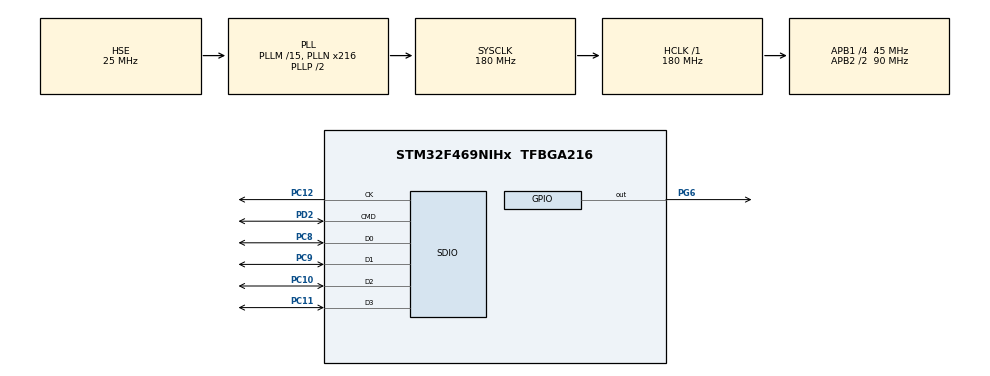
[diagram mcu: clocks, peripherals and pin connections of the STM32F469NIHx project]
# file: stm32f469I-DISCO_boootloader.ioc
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Dma.Request0=SDIO_RX
Dma.Request1=SDIO_TX
Dma.SDIO_RX.0.Direction=DMA_PERIPH_TO_MEMORY
Dma.SDIO_RX.0.FIFOMode=DMA_FIFOMODE_ENABLE
Dma.SDIO_RX.0.FIFOThreshold=DMA_FIFO_THRESHOLD_FULL
Dma.SDIO_RX.0.Instance=DMA2_Stream3
Dma.SDIO_RX.0.MemBurst=DMA_MBURST_INC4
Dma.SDIO_RX.0.MemDataAlignment=DMA_MDATAALIGN_WORD
Dma.SDIO_RX.0.MemInc=DMA_MINC_ENABLE
Dma.SDIO_RX.0.Mode=DMA_PFCTRL
Dma.SDIO_RX.0.PeriphBurst=DMA_PBURST_INC4
Dma.SDIO_RX.0.PeriphDataAlignment=DMA_PDATAALIGN_WORD
Dma.SDIO_RX.0.PeriphInc=DMA_PINC_DISABLE
Dma.SDIO_RX.0.Priority=DMA_PRIORITY_LOW
Dma.SDIO_TX.1.Direction=DMA_MEMORY_TO_PERIPH
Dma.SDIO_TX.1.FIFOMode=DMA_FIFOMODE_ENABLE
Dma.SDIO_TX.1.FIFOThreshold=DMA_FIFO_THRESHOLD_FULL
Dma.SDIO_TX.1.Instance=DMA2_Stream6
Dma.SDIO_TX.1.MemBurst=DMA_MBURST_INC4
Dma.SDIO_TX.1.MemDataAlignment=DMA_MDATAALIGN_WORD
Dma.SDIO_TX.1.MemInc=DMA_MINC_ENABLE
Dma.SDIO_TX.1.Mode=DMA_PFCTRL
Dma.SDIO_TX.1.PeriphBurst=DMA_PBURST_INC4
Dma.SDIO_TX.1.PeriphDataAlignment=DMA_PDATAALIGN_WORD
Dma.SDIO_TX.1.PeriphInc=DMA_PINC_DISABLE
Dma.SDIO_TX.1.Priority=DMA_PRIORITY_LOW
FATFS.USE_DMA_CODE_SD=1
FATFS._MAX_SS=4096
FREERTOS.Tasks01=defaultTask,0,128,StartDefaultTask,Default,NULL
Mcu.Family=STM32F4
Mcu.Name=STM32F469NIHx
Mcu.Package=TFBGA216
NVIC.DMA2_Stream3_IRQn=true\:5\:0\:false\:false\:true\:true\:false\:true
NVIC.DMA2_Stream6_IRQn=true\:5\:0\:false\:false\:true\:true\:false\:true
NVIC.PriorityGroup=NVIC_PRIORITYGROUP_4
NVIC.SDIO_IRQn=true\:5\:0\:false\:false\:true\:true\:true\:true
NVIC.TIM6_DAC_IRQn=true\:0\:0\:false\:false\:true\:false\:false\:true
NVIC.TimeBase=TIM6_DAC_IRQn
NVIC.TimeBaseIP=TIM6
PC10.Mode=SD_4_bits_Wide_bus
PC10.Signal=SDIO_D2
PC11.Mode=SD_4_bits_Wide_bus
PC11.Signal=SDIO_D3
PC12.Mode=SD_4_bits_Wide_bus
PC12.Signal=SDIO_CK
PC8.Mode=SD_4_bits_Wide_bus
PC8.Signal=SDIO_D0
PC9.Mode=SD_4_bits_Wide_bus
PC9.Signal=SDIO_D1
PD2.Mode=SD_4_bits_Wide_bus
PD2.Signal=SDIO_CMD
PG6.Signal=GPIO_Output
PH0/OSC_IN.Mode=HSE-External-Oscillator
PH0/OSC_IN.Signal=RCC_OSC_IN
PH1/OSC_OUT.Mode=HSE-External-Oscillator
PH1/OSC_OUT.Signal=RCC_OSC_OUT
ProjectManager.HeapSize=0x200
ProjectManager.StackSize=0x400
ProjectManager.TargetToolchain=TrueSTUDIO
RCC.AHBFreq_Value=180000000
RCC.APB1CLKDivider=RCC_HCLK_DIV4
RCC.APB1Freq_Value=45000000
RCC.APB1TimFreq_Value=90000000
RCC.APB2CLKDivider=RCC_HCLK_DIV2
RCC.APB2Freq_Value=90000000
RCC.APB2TimFreq_Value=180000000
RCC.CortexFreq_Value=180000000
RCC.HCLKFreq_Value=180000000
RCC.PLLM=15
RCC.PLLN=216
RCC.PLLQ=8
RCC.PLLSourceVirtual=RCC_PLLSOURCE_HSE
RCC.SYSCLKFreq_VALUE=180000000
RCC.SYSCLKSource=RCC_SYSCLKSOURCE_PLLCLK
RCC.USBFreq_Value=45000000
RCC.VCOOutputFreq_Value=360000000
VP_FATFS_VS_SDIO.Mode=SDIO
VP_FREERTOS_VS_CMSIS_V1.Mode=CMSIS_V1
VP_SYS_VS_tim6.Mode=TIM6
board=STM32F469I-DISCO

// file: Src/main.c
/* USER CODE BEGIN Header */
/**
  ******************************************************************************
  * @file           : main.c
  * @brief          : Main program body
  ******************************************************************************
  * @attention
  *
  * <h2><center>&copy; Copyright (c) 2019 STMicroelectronics.
  * All rights reserved.</center></h2>
  *
  * This software component is licensed by ST under Ultimate Liberty license
  * SLA0044, the "License"; You may not use this file except in compliance with
  * the License. You may obtain a copy of the License at:
  *                             www.st.com/SLA0044
  *
  ******************************************************************************
  */
/* USER CODE END Header */

#include "main.h"
#include "cmsis_os.h"
#include "fatfs.h"

SD_HandleTypeDef hsd;
DMA_HandleTypeDef hdma_sdio_rx;
DMA_HandleTypeDef hdma_sdio_tx;

osThreadId defaultTaskHandle;

void SystemClock_Config(void);
static void MX_GPIO_Init(void);
static void MX_DMA_Init(void);
static void MX_SDIO_SD_Init(void);
void StartDefaultTask(void const * argument);

int main(void)
{

  /* MCU Configuration--------------------------------------------------------*/

  /* Reset of all peripherals, Initializes the Flash interface and the Systick. */
  HAL_Init();

  /* Configure the system clock */
  SystemClock_Config();

  /* Initialize all configured peripherals */
  MX_GPIO_Init();
  MX_DMA_Init();
  MX_SDIO_SD_Init();

  /* Create the thread(s) */
  /* definition and creation of defaultTask */
  osThreadDef(defaultTask, StartDefaultTask, osPriorityNormal, 0, 128);
  defaultTaskHandle = osThreadCreate(osThread(defaultTask), NULL);

  /* Start scheduler */
  osKernelStart();

  /* We should never get here as control is now taken by the scheduler */

  /* Infinite loop */
  while (1)
  {

  }
}

void SystemClock_Config(void)
{
  RCC_OscInitTypeDef RCC_OscInitStruct = {0};
  RCC_ClkInitTypeDef RCC_ClkInitStruct = {0};
  RCC_PeriphCLKInitTypeDef PeriphClkInitStruct = {0};

  /** Configure the main internal regulator output voltage
  */
  __HAL_RCC_PWR_CLK_ENABLE();
  __HAL_PWR_VOLTAGESCALING_CONFIG(PWR_REGULATOR_VOLTAGE_SCALE1);
  /** Initializes the CPU, AHB and APB busses clocks
  */
  RCC_OscInitStruct.OscillatorType = RCC_OSCILLATORTYPE_HSE;
  RCC_OscInitStruct.HSEState = RCC_HSE_ON;
  RCC_OscInitStruct.PLL.PLLState = RCC_PLL_ON;
  RCC_OscInitStruct.PLL.PLLSource = RCC_PLLSOURCE_HSE;
  RCC_OscInitStruct.PLL.PLLM = 15;
  RCC_OscInitStruct.PLL.PLLN = 216;
  RCC_OscInitStruct.PLL.PLLP = RCC_PLLP_DIV2;
  RCC_OscInitStruct.PLL.PLLQ = 8;
  RCC_OscInitStruct.PLL.PLLR = 2;
  if (HAL_RCC_OscConfig(&RCC_OscInitStruct) != HAL_OK)
  {
    Error_Handler();
  }
  /** Activate the Over-Drive mode
  */
  if (HAL_PWREx_EnableOverDrive() != HAL_OK)
  {
    Error_Handler();
  }
  /** Initializes the CPU, AHB and APB busses clocks
  */
  RCC_ClkInitStruct.ClockType = RCC_CLOCKTYPE_HCLK|RCC_CLOCKTYPE_SYSCLK
                              |RCC_CLOCKTYPE_PCLK1|RCC_CLOCKTYPE_PCLK2;
  RCC_ClkInitStruct.SYSCLKSource = RCC_SYSCLKSOURCE_PLLCLK;
  RCC_ClkInitStruct.AHBCLKDivider = RCC_SYSCLK_DIV1;
  RCC_ClkInitStruct.APB1CLKDivider = RCC_HCLK_DIV4;
  RCC_ClkInitStruct.APB2CLKDivider = RCC_HCLK_DIV2;

  if (HAL_RCC_ClockConfig(&RCC_ClkInitStruct, FLASH_LATENCY_5) != HAL_OK)
  {
    Error_Handler();
  }
  PeriphClkInitStruct.PeriphClockSelection = RCC_PERIPHCLK_SDIO|RCC_PERIPHCLK_CLK48;
  PeriphClkInitStruct.Clk48ClockSelection = RCC_CLK48CLKSOURCE_PLLQ;
  PeriphClkInitStruct.SdioClockSelection = RCC_SDIOCLKSOURCE_CLK48;
  if (HAL_RCCEx_PeriphCLKConfig(&PeriphClkInitStruct) != HAL_OK)
  {
    Error_Handler();
  }
}

static void MX_SDIO_SD_Init(void)
{

  hsd.Instance = SDIO;
  hsd.Init.ClockEdge = SDIO_CLOCK_EDGE_RISING;
  hsd.Init.ClockBypass = SDIO_CLOCK_BYPASS_DISABLE;
  hsd.Init.ClockPowerSave = SDIO_CLOCK_POWER_SAVE_DISABLE;
  hsd.Init.BusWide = SDIO_BUS_WIDE_1B;
  hsd.Init.HardwareFlowControl = SDIO_HARDWARE_FLOW_CONTROL_DISABLE;
  hsd.Init.ClockDiv = 0;

}

static void MX_DMA_Init(void)
{

  /* DMA controller clock enable */
  __HAL_RCC_DMA2_CLK_ENABLE();

  /* DMA interrupt init */
  /* DMA2_Stream3_IRQn interrupt configuration */
  HAL_NVIC_SetPriority(DMA2_Stream3_IRQn, 5, 0);
  HAL_NVIC_EnableIRQ(DMA2_Stream3_IRQn);
  /* DMA2_Stream6_IRQn interrupt configuration */
  HAL_NVIC_SetPriority(DMA2_Stream6_IRQn, 5, 0);
  HAL_NVIC_EnableIRQ(DMA2_Stream6_IRQn);

}

static void MX_GPIO_Init(void)
{
  GPIO_InitTypeDef GPIO_InitStruct = {0};

  /* GPIO Ports Clock Enable */
  __HAL_RCC_GPIOC_CLK_ENABLE();
  __HAL_RCC_GPIOD_CLK_ENABLE();
  __HAL_RCC_GPIOH_CLK_ENABLE();
  __HAL_RCC_GPIOG_CLK_ENABLE();

  /*Configure GPIO pin Output Level */
  HAL_GPIO_WritePin(GPIOG, GPIO_PIN_6, GPIO_PIN_RESET);

  /*Configure GPIO pin : PG6 */
  GPIO_InitStruct.Pin = GPIO_PIN_6;
  GPIO_InitStruct.Mode = GPIO_MODE_OUTPUT_PP;
  GPIO_InitStruct.Pull = GPIO_NOPULL;
  GPIO_InitStruct.Speed = GPIO_SPEED_FREQ_LOW;
  HAL_GPIO_Init(GPIOG, &GPIO_InitStruct);

}

void StartDefaultTask(void const * argument)
{
  /* init code for FATFS */
  MX_FATFS_Init();
  /* USER CODE BEGIN 5 */
  /* Infinite loop */
  for(;;)
  {
    osDelay(200);
    HAL_GPIO_TogglePin(GPIOG, GPIO_PIN_6);
  }
  /* USER CODE END 5 */
}

void HAL_TIM_PeriodElapsedCallback(TIM_HandleTypeDef *htim)
{
  if (htim->Instance == TIM6) {
    HAL_IncTick();
  }
}

void Error_Handler(void)
{
}

/************************ (C) COPYRIGHT STMicroelectronics *****END OF FILE****/
